# GD32C231 register map
File version: 1.0
CPU: CM23 r0p0, little endian, MPU, FPU, 4 interrupt priority bits
Registers are 32-bit, read-write, reset 0x0 unless marked. A register's access mark holds for its fields unless they carry their own. Offsets are from the block's base; [hi:lo] are bit positions; {n}, {i} and the like mark numbered series; 'fields as' and 'values as' point back to an identical list.

## SYSCFG — System and memory architectur
Base 0x40010000
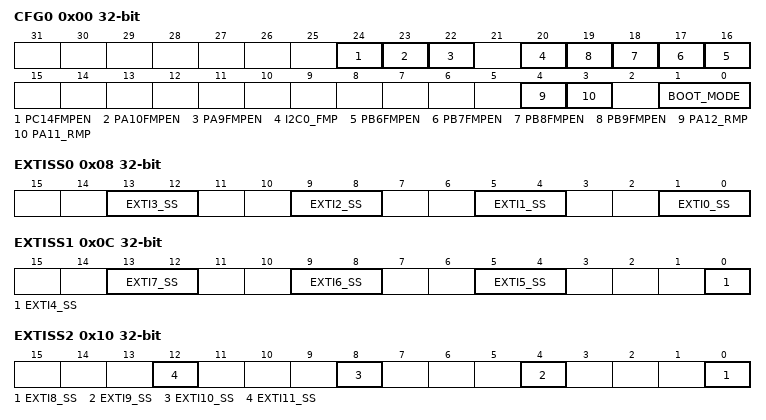
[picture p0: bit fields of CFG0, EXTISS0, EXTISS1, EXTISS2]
0x00 CFG0 — System configuration register 0
  [24] PC14FMPEN — I2C Fm+ mode on PC14 pin enable (for GD32C231xx / GD32C221xx series)
  [23] PA10FMPEN — I2C Fm+ mode on PA10 pin enable (for GD32C231xx / GD32C221xx series)
  [22] PA9FMPEN — I2C Fm+ mode on PA9 pin enable (for GD32C231xx / GD32C221xx series)
  [20] I2C0_FMP — Fast Mode Plus (FM+) enable for I2C0 (for GD32C231xx / GD32C221xx series)
  [n+10] PB{n}FMPEN (n=6..9) — I2C Fm+ mode on PB{n} pin enable (for GD32C231xx / GD32C221xx series)
  [4] PA12_RMP — PA12 pin remapping
  [3] PA11_RMP — PA11 pin remapping This bit is set and cleared by software. When set, it remaps the PA11 pin to operate as PA9 GPIO port, instead as PA11 GPIO port.
  [1:0] BOOT_MODE — Boot mode (Refer to Boot configuration for details)
0x08 EXTISS0 — EXTI sources selection register 0
  [4n+1:4n] EXTI{n}_SS (n=0..3) — EXTI {n} sources selection
0x0C EXTISS1 — EXTI sources selection register 1
  [13:12] EXTI7_SS — EXTI 7 sources selection
  [9:8] EXTI6_SS — EXTI 6 sources selection
  [5:4] EXTI5_SS — EXTI 5 sources selection
  [0] EXTI4_SS — EXTI 4 sources selection
0x10 EXTISS2 — EXTI sources selection register 2
  [4n-32] EXTI{n}_SS (n=8..11) — EXTI {n} sources selection
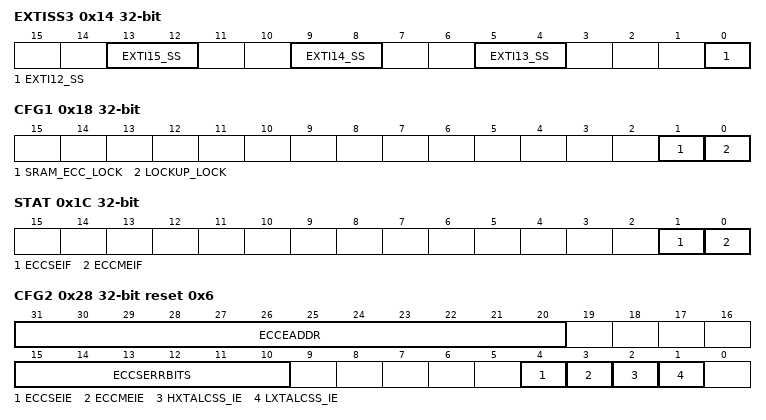
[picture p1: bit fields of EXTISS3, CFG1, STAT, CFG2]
0x14 EXTISS3 — EXTI sources selection register 3
  [13:12] EXTI15_SS — EXTI 15 sources selection
  [9:8] EXTI14_SS — EXTI 14 sources selection
  [5:4] EXTI13_SS — EXTI 13 sources selection
  [0] EXTI12_SS — EXTI 12 sources selection
0x18 CFG1 — System configuration register 1
  [1] SRAM_ECC_LOCK — SRAM ECC check error lock
  [0] LOCKUP_LOCK — Cortex-M23 LOCKUP output lock
0x1C STAT — System status register
  [1] ECCSEIF — SRAM single bit correction event flag
  [0] ECCMEIF — SRAM two bits non-correction event flag
0x28 CFG2 access per field reset 0x6 — SYSCFG configuration register 2
  [31:20] ECCEADDR ro — Indicates the last ECC event on SRAM occurred. (for GD32C231xx / GD32C221xx series)
  [15:10] ECCSERRBITS ro — Indicates the error bit(for GD32C231xx / GD32C221xx series)
  [4] ECCSEIE rw — Single bit correction error interrupt enable(for GD32C231xx / GD32C221xx series)
  [3] ECCMEIE rw — Multi-bits (two bits) non-correction error NMI interrupt enable (for GD32C231xx / GD32C221xx series)
  [2] HXTALCSS_IE rw — HXTAL css interrupt enable
  [1] LXTALCSS_IE rw — LXTAL css interrupt enable
0x100 CPU_IRQ_LAT — IRQ latency register
  [7:0] IRQ_LATENCY — IRQ_LATENCY specifies the minimum number of cycles between an interrupt that becomes pended in the NVIC, and the vector fetch for that interrupt being issued on the AHB-Lite interface.
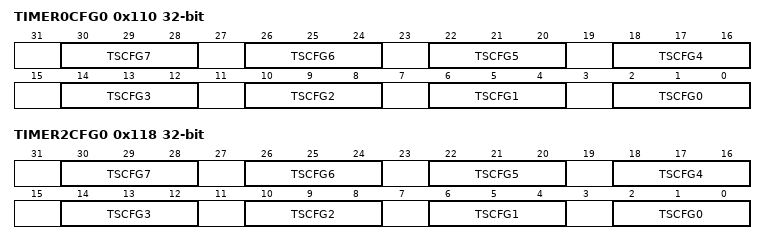
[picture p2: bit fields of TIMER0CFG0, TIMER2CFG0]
0x110 TIMER0CFG0 — TIMERx configuration register 0
  [30:28] TSCFG7 — Restart event mode configuration
  [26:24] TSCFG6 — External clock mode 0 configuration
  [22:20] TSCFG5 — Event mode configuration
  [18:16] TSCFG4 — Pause mode configuration
  [14:12] TSCFG3 — Restart mode configuration
  [10:8] TSCFG2 — Quadrature decoder mode 2 configuration
  [6:4] TSCFG1 — Quadrature decoder mode 1 configuration
  [2:0] TSCFG0 — Quadrature decoder mode 0 configuration
0x114 TIMER0CFG1 — TIMERx configuration register 1
  [2:0] TSCFG8 — Internal trigger input source configuration
0x118 TIMER2CFG0 — TIMER2 configuration register 0
  fields as TIMER0CFG0
0x11C TIMER2CFG1 — TIMER2 configuration register 1
  [2:0] TSCFG8 — Internal trigger input source configuration

## TIMER13 — General-level0-timers
Base 0x40002000
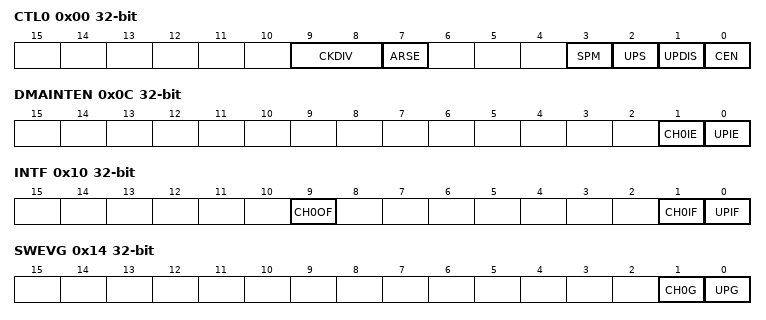
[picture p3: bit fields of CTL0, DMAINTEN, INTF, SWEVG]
0x00 CTL0 — Control register 0
  [9:8] CKDIV — Clock division
  [7] ARSE — Auto-reload shadow enable
  [3] SPM — Single pulse mode.
  [2] UPS — Update source
  [1] UPDIS — Update disable.
  [0] CEN — Counter enable
0x0C DMAINTEN — Interrupt enable register
  [1] CH0IE — Channel 0 capture/compare interrupt enable
  [0] UPIE — Update interrupt enable
0x10 INTF — Interrupt flag register
  [9] CH0OF — Channel 0 over capture flag
  [1] CH0IF — Channel 0 capture/compare interrupt flag
  [0] UPIF — Update interrupt flag
0x14 SWEVG wo — Software event generation register
  [1] CH0G — Channel 0 capture or compare event generation
  [0] UPG — This bit can be set by software, and cleared by hardware automatically. When this bit is set, the counter is cleared. The prescaler counter is cleared at the same time.
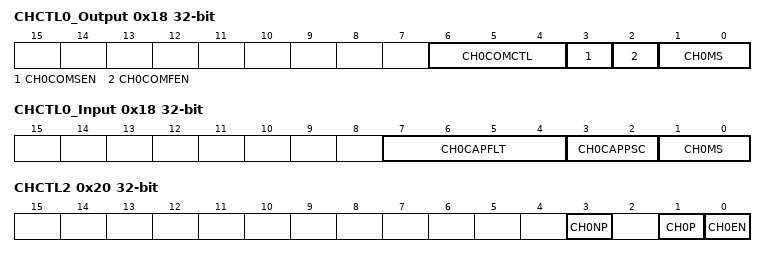
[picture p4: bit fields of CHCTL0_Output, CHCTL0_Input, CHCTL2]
0x18 CHCTL0_Output — channel control register 0 (output mode)
  [6:4] CH0COMCTL — Channel 0 compare output control
  [3] CH0COMSEN — Channel 0 compare output shadow enable
  [2] CH0COMFEN — Channel 0 output compare fast enable
  [1:0] CH0MS — Channel 0 I/O mode selection
0x18 CHCTL0_Input (alternate view of CHCTL0_Output) — channel control register 0 (input mode)
  [7:4] CH0CAPFLT — Channel 0 input capture filter control
  [3:2] CH0CAPPSC — Channel 0 input capture prescaler
  [1:0] CH0MS — Channel 0 mode selection
0x20 CHCTL2 — Channel control register 2
  [3] CH0NP — Channel 0 complementary output polarity
  [1] CH0P — Channel 0 capture/compare polarity
  [0] CH0EN — Channel 0 capture/compare function enable
0x24 CNT — Counter register
  [15:0] CNT — This bit-filed indicates the current counter value. Writing to this bit-filed can change the value of the counter.
0x28 PSC — Prescaler register
  [15:0] PSC — Prescaler value of the counter clock
0x2C CAR reset 0xFFFF — Counter auto reload register
  [15:0] CARL — Counter auto reload value
0x34 CH0CV — Channel 0 capture/compare value register
  [15:0] CH0VAL — Capture or compare value of channel0
0x68 INSEL — input selection register
  [3:0] CI0_SEL — Channel 0 input selection
0xFC CFG — Configuration register
  [1] CHVSEL — Write CHxVAL register selection
